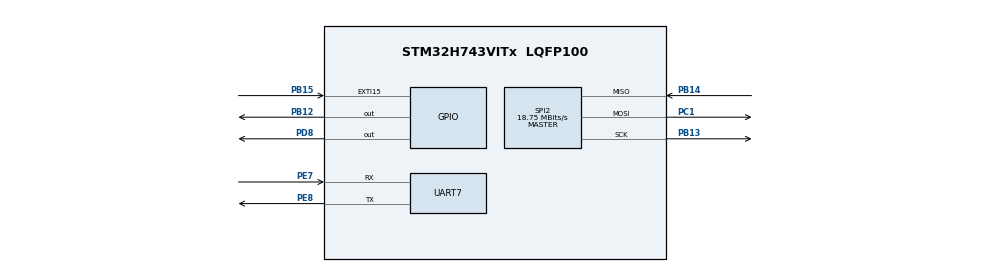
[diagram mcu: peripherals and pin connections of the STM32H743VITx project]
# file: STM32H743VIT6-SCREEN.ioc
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Mcu.Family=STM32H7
Mcu.Name=STM32H743VITx
Mcu.Package=LQFP100
NVIC.EXTI15_10_IRQn=true\:0\:0\:false\:false\:true\:true\:true\:true
NVIC.PriorityGroup=NVIC_PRIORITYGROUP_4
PB12.Signal=GPIO_Output
PB13.Mode=Full_Duplex_Master
PB13.Signal=SPI2_SCK
PB14.Mode=Full_Duplex_Master
PB14.Signal=SPI2_MISO
PB15.GPIO_ModeDefaultEXTI=GPIO_MODE_IT_FALLING
PB15.Signal=GPXTI15
PC1.Mode=Full_Duplex_Master
PC1.Signal=SPI2_MOSI
PD8.Signal=GPIO_Output
PE7.Mode=Asynchronous
PE7.Signal=UART7_RX
PE8.Mode=Asynchronous
PE8.Signal=UART7_TX
ProjectManager.HeapSize=0x200
ProjectManager.StackSize=0x400
ProjectManager.TargetToolchain=STM32CubeIDE
RCC.ADCFreq_Value=129000000
RCC.APB1Freq_Value=32000000
RCC.APB2Freq_Value=64000000
RCC.APB3Freq_Value=64000000
RCC.APB4Freq_Value=64000000
RCC.CortexFreq_Value=64000000
RCC.D2PPRE1=RCC_APB1_DIV2
RCC.DIVM1=4
RCC.DIVN1=9
RCC.HCLKFreq_Value=64000000
RCC.PLLFRACN=3072
RCC.SYSCLKFreq_VALUE=64000000
RCC.USBCLockSelection=RCC_USBCLKSOURCE_HSI48
RCC.USBFreq_Value=48000000
SPI2.BaudRatePrescaler=SPI_BAUDRATEPRESCALER_4
SPI2.CLKPolarity=SPI_POLARITY_HIGH
SPI2.CalculateBaudRate=18.75 MBits/s
SPI2.DataSize=SPI_DATASIZE_8BIT
SPI2.Direction=SPI_DIRECTION_2LINES
SPI2.Mode=SPI_MODE_MASTER
SPI2.VirtualType=VM_MASTER
board=custom

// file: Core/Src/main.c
/* USER CODE BEGIN Header */
/**
  ******************************************************************************
  * @file           : main.c
  * @brief          : Main program body
  ******************************************************************************
  * @attention
  *
  * Copyright (c) 2022 STMicroelectronics.
  * All rights reserved.
  *
  * This software is licensed under terms that can be found in the LICENSE file
  * in the root directory of this software component.
  * If no LICENSE file comes with this software, it is provided AS-IS.
  *
  ******************************************************************************
  */
/* USER CODE END Header */
#include "main.h"

SPI_HandleTypeDef hspi2;

UART_HandleTypeDef huart7;

void SystemClock_Config(void);
static void MX_GPIO_Init(void);
static void MX_SPI2_Init(void);
static void MX_UART7_Init(void);

int main(void)
{

  /* MCU Configuration--------------------------------------------------------*/

  /* Reset of all peripherals, Initializes the Flash interface and the Systick. */
  HAL_Init();

  /* Configure the system clock */
  SystemClock_Config();

  /* Initialize all configured peripherals */
  MX_GPIO_Init();
  MX_SPI2_Init();
  MX_UART7_Init();
  /* USER CODE BEGIN 2 */
  MODE_init(MODE1,&huart7, &hspi2);
  /* USER CODE END 2 */

  /* Infinite loop */
  while (1)
  {

  }
}

void SystemClock_Config(void)
{
  RCC_OscInitTypeDef RCC_OscInitStruct = {0};
  RCC_ClkInitTypeDef RCC_ClkInitStruct = {0};

  /** Supply configuration update enable
  */
  HAL_PWREx_ConfigSupply(PWR_LDO_SUPPLY);

  /** Configure the main internal regulator output voltage
  */
  __HAL_PWR_VOLTAGESCALING_CONFIG(PWR_REGULATOR_VOLTAGE_SCALE3);

  while(!__HAL_PWR_GET_FLAG(PWR_FLAG_VOSRDY)) {}

  /** Initializes the RCC Oscillators according to the specified parameters
  * in the RCC_OscInitTypeDef structure.
  */
  RCC_OscInitStruct.OscillatorType = RCC_OSCILLATORTYPE_HSI;
  RCC_OscInitStruct.HSIState = RCC_HSI_DIV1;
  RCC_OscInitStruct.HSICalibrationValue = RCC_HSICALIBRATION_DEFAULT;
  RCC_OscInitStruct.PLL.PLLState = RCC_PLL_ON;
  RCC_OscInitStruct.PLL.PLLSource = RCC_PLLSOURCE_HSI;
  RCC_OscInitStruct.PLL.PLLM = 4;
  RCC_OscInitStruct.PLL.PLLN = 9;
  RCC_OscInitStruct.PLL.PLLP = 2;
  RCC_OscInitStruct.PLL.PLLQ = 2;
  RCC_OscInitStruct.PLL.PLLR = 2;
  RCC_OscInitStruct.PLL.PLLRGE = RCC_PLL1VCIRANGE_3;
  RCC_OscInitStruct.PLL.PLLVCOSEL = RCC_PLL1VCOMEDIUM;
  RCC_OscInitStruct.PLL.PLLFRACN = 3072;
  if (HAL_RCC_OscConfig(&RCC_OscInitStruct) != HAL_OK)
  {
    Error_Handler();
  }

  /** Initializes the CPU, AHB and APB buses clocks
  */
  RCC_ClkInitStruct.ClockType = RCC_CLOCKTYPE_HCLK|RCC_CLOCKTYPE_SYSCLK
                              |RCC_CLOCKTYPE_PCLK1|RCC_CLOCKTYPE_PCLK2
                              |RCC_CLOCKTYPE_D3PCLK1|RCC_CLOCKTYPE_D1PCLK1;
  RCC_ClkInitStruct.SYSCLKSource = RCC_SYSCLKSOURCE_HSI;
  RCC_ClkInitStruct.SYSCLKDivider = RCC_SYSCLK_DIV1;
  RCC_ClkInitStruct.AHBCLKDivider = RCC_HCLK_DIV1;
  RCC_ClkInitStruct.APB3CLKDivider = RCC_APB3_DIV1;
  RCC_ClkInitStruct.APB1CLKDivider = RCC_APB1_DIV2;
  RCC_ClkInitStruct.APB2CLKDivider = RCC_APB2_DIV1;
  RCC_ClkInitStruct.APB4CLKDivider = RCC_APB4_DIV1;

  if (HAL_RCC_ClockConfig(&RCC_ClkInitStruct, FLASH_LATENCY_1) != HAL_OK)
  {
    Error_Handler();
  }
}

static void MX_SPI2_Init(void)
{

  /* SPI2 parameter configuration*/
  hspi2.Instance = SPI2;
  hspi2.Init.Mode = SPI_MODE_MASTER;
  hspi2.Init.Direction = SPI_DIRECTION_2LINES;
  hspi2.Init.DataSize = SPI_DATASIZE_8BIT;
  hspi2.Init.CLKPolarity = SPI_POLARITY_HIGH;
  hspi2.Init.CLKPhase = SPI_PHASE_1EDGE;
  hspi2.Init.NSS = SPI_NSS_SOFT;
  hspi2.Init.BaudRatePrescaler = SPI_BAUDRATEPRESCALER_4;
  hspi2.Init.FirstBit = SPI_FIRSTBIT_MSB;
  hspi2.Init.TIMode = SPI_TIMODE_DISABLE;
  hspi2.Init.CRCCalculation = SPI_CRCCALCULATION_DISABLE;
  hspi2.Init.CRCPolynomial = 0x0;
  hspi2.Init.NSSPMode = SPI_NSS_PULSE_ENABLE;
  hspi2.Init.NSSPolarity = SPI_NSS_POLARITY_LOW;
  hspi2.Init.FifoThreshold = SPI_FIFO_THRESHOLD_01DATA;
  hspi2.Init.TxCRCInitializationPattern = SPI_CRC_INITIALIZATION_ALL_ZERO_PATTERN;
  hspi2.Init.RxCRCInitializationPattern = SPI_CRC_INITIALIZATION_ALL_ZERO_PATTERN;
  hspi2.Init.MasterSSIdleness = SPI_MASTER_SS_IDLENESS_00CYCLE;
  hspi2.Init.MasterInterDataIdleness = SPI_MASTER_INTERDATA_IDLENESS_00CYCLE;
  hspi2.Init.MasterReceiverAutoSusp = SPI_MASTER_RX_AUTOSUSP_DISABLE;
  hspi2.Init.MasterKeepIOState = SPI_MASTER_KEEP_IO_STATE_DISABLE;
  hspi2.Init.IOSwap = SPI_IO_SWAP_DISABLE;
  if (HAL_SPI_Init(&hspi2) != HAL_OK)
  {
    Error_Handler();
  }

}

static void MX_UART7_Init(void)
{

  huart7.Instance = UART7;
  huart7.Init.BaudRate = 115200;
  huart7.Init.WordLength = UART_WORDLENGTH_8B;
  huart7.Init.StopBits = UART_STOPBITS_1;
  huart7.Init.Parity = UART_PARITY_NONE;
  huart7.Init.Mode = UART_MODE_TX_RX;
  huart7.Init.HwFlowCtl = UART_HWCONTROL_NONE;
  huart7.Init.OverSampling = UART_OVERSAMPLING_16;
  huart7.Init.OneBitSampling = UART_ONE_BIT_SAMPLE_DISABLE;
  huart7.Init.ClockPrescaler = UART_PRESCALER_DIV1;
  huart7.AdvancedInit.AdvFeatureInit = UART_ADVFEATURE_NO_INIT;
  if (HAL_UART_Init(&huart7) != HAL_OK)
  {
    Error_Handler();
  }
  if (HAL_UARTEx_SetTxFifoThreshold(&huart7, UART_TXFIFO_THRESHOLD_1_8) != HAL_OK)
  {
    Error_Handler();
  }
  if (HAL_UARTEx_SetRxFifoThreshold(&huart7, UART_RXFIFO_THRESHOLD_1_8) != HAL_OK)
  {
    Error_Handler();
  }
  if (HAL_UARTEx_DisableFifoMode(&huart7) != HAL_OK)
  {
    Error_Handler();
  }

}

static void MX_GPIO_Init(void)
{
  GPIO_InitTypeDef GPIO_InitStruct = {0};

  /* GPIO Ports Clock Enable */
  __HAL_RCC_GPIOC_CLK_ENABLE();
  __HAL_RCC_GPIOE_CLK_ENABLE();
  __HAL_RCC_GPIOB_CLK_ENABLE();
  __HAL_RCC_GPIOD_CLK_ENABLE();

  /*Configure GPIO pin Output Level */
  HAL_GPIO_WritePin(GPIOB, GPIO_PIN_12, GPIO_PIN_RESET);

  /*Configure GPIO pin Output Level */
  HAL_GPIO_WritePin(GPIOD, GPIO_PIN_8, GPIO_PIN_RESET);

  /*Configure GPIO pin : PB12 */
  GPIO_InitStruct.Pin = GPIO_PIN_12;
  GPIO_InitStruct.Mode = GPIO_MODE_OUTPUT_PP;
  GPIO_InitStruct.Pull = GPIO_NOPULL;
  GPIO_InitStruct.Speed = GPIO_SPEED_FREQ_LOW;
  HAL_GPIO_Init(GPIOB, &GPIO_InitStruct);

  /*Configure GPIO pin : PB15 */
  GPIO_InitStruct.Pin = GPIO_PIN_15;
  GPIO_InitStruct.Mode = GPIO_MODE_IT_FALLING;
  GPIO_InitStruct.Pull = GPIO_NOPULL;
  HAL_GPIO_Init(GPIOB, &GPIO_InitStruct);

  /*Configure GPIO pin : PD8 */
  GPIO_InitStruct.Pin = GPIO_PIN_8;
  GPIO_InitStruct.Mode = GPIO_MODE_OUTPUT_PP;
  GPIO_InitStruct.Pull = GPIO_NOPULL;
  GPIO_InitStruct.Speed = GPIO_SPEED_FREQ_LOW;
  HAL_GPIO_Init(GPIOD, &GPIO_InitStruct);

  /* EXTI interrupt init*/
  HAL_NVIC_SetPriority(EXTI15_10_IRQn, 0, 0);
  HAL_NVIC_EnableIRQ(EXTI15_10_IRQn);

}

/* USER CODE BEGIN 4 */
void HAL_GPIO_EXTI_Callback(uint16_t GPIO_Pin)
{
    if(GPIO_Pin == GPIO_PIN_15) // If The INT Source Is EXTI Line9 ( Pin)
    {
    	MODE_touchInterrupt();
    }
}
/* USER CODE END 4 */

void Error_Handler(void)
{
  __disable_irq();
  while (1)
  {
  }
}
